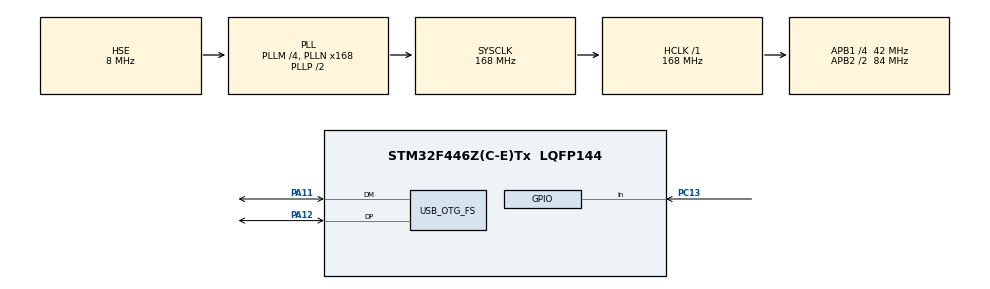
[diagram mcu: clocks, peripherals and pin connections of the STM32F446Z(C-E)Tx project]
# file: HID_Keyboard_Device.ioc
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Mcu.Family=STM32F4
Mcu.Name=STM32F446Z(C-E)Tx
Mcu.Package=LQFP144
NVIC.OTG_FS_IRQn=true\:0\:0\:false\:false\:true\:false\:true
NVIC.PriorityGroup=NVIC_PRIORITYGROUP_4
PA11.Mode=Device_Only
PA11.Signal=USB_OTG_FS_DM
PA12.Mode=Device_Only
PA12.Signal=USB_OTG_FS_DP
PC13.Signal=GPIO_Input
PH0-OSC_IN.Mode=HSE-External-Clock-Source
PH0-OSC_IN.Signal=RCC_OSC_IN
PH1-OSC_OUT.Mode=HSE-External-Clock-Source
PH1-OSC_OUT.Signal=RCC_OSC_OUT
ProjectManager.HeapSize=0x200
ProjectManager.StackSize=0x400
ProjectManager.TargetToolchain=STM32CubeIDE
RCC.AHBFreq_Value=168000000
RCC.APB1CLKDivider=RCC_HCLK_DIV4
RCC.APB1Freq_Value=42000000
RCC.APB1TimFreq_Value=84000000
RCC.APB2CLKDivider=RCC_HCLK_DIV2
RCC.APB2Freq_Value=84000000
RCC.APB2TimFreq_Value=168000000
RCC.CortexFreq_Value=168000000
RCC.HCLKFreq_Value=168000000
RCC.HSE_VALUE=8000000
RCC.PLLM=4
RCC.PLLN=168
RCC.PLLQ=7
RCC.SYSCLKFreq_VALUE=168000000
RCC.SYSCLKSource=RCC_SYSCLKSOURCE_PLLCLK
RCC.USBFreq_Value=48000000
RCC.VCOOutputFreq_Value=336000000
USB_DEVICE.CLASS_NAME_FS=HID
USB_DEVICE.PID_HID_FS=22316
USB_DEVICE.VirtualMode-HID_FS=Hid
USB_DEVICE.VirtualModeFS=Hid_FS
USB_OTG_FS.VirtualMode=Device_Only
VP_USB_DEVICE_VS_USB_DEVICE_HID_FS.Mode=HID_FS
board=HID_Keyboard_Device

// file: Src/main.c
/* USER CODE BEGIN Header */
/**
  ******************************************************************************
  * @file           : main.c
  * @brief          : Main program body
  ******************************************************************************
  * @attention
  *
  * <h2><center>&copy; Copyright (c) 2019 STMicroelectronics.
  * All rights reserved.</center></h2>
  *
  * This software component is licensed by ST under Ultimate Liberty license
  * SLA0044, the "License"; You may not use this file except in compliance with
  * the License. You may obtain a copy of the License at:
  *                             www.st.com/SLA0044
  *
  ******************************************************************************
  */
/* USER CODE END Header */

#include "main.h"
#include "usb_device.h"

/* USER CODE BEGIN Includes */
#include "usbd_hid.h"
/* USER CODE END Includes */

/* USER CODE BEGIN PV */
/* Private variables ---------------------------------------------------------*/
extern USBD_HandleTypeDef hUsbDeviceFS;
/* USER CODE END PV */

void SystemClock_Config(void);
static void MX_GPIO_Init(void);
/* USER CODE BEGIN PFP */
/* Private function prototypes -----------------------------------------------*/
uint8_t buffer[8];
/* USER CODE END PFP */

int main(void)
{

  /* MCU Configuration--------------------------------------------------------*/

  /* Reset of all peripherals, Initializes the Flash interface and the Systick. */
  HAL_Init();

  /* Configure the system clock */
  SystemClock_Config();

  /* Initialize all configured peripherals */
  MX_GPIO_Init();
  MX_USB_DEVICE_Init();
  /* USER CODE BEGIN 2 */
  buffer[0]=1;//reportID
  buffer[1]=0;//modifier
  buffer[2]=0;//OEM
  buffer[3]=0;//keycode data
  buffer[4]=0;//keycode data
  buffer[5]=0;//keycode data
  buffer[6]=0;//keycode data
  buffer[7]=0;//keycode data

  /* USER CODE END 2 */

  /* Infinite loop */
  while (1)
  {

    /* USER CODE BEGIN 3 */
  if(HAL_GPIO_ReadPin(GPIOC,GPIO_PIN_13)==GPIO_PIN_SET)    {
	// Begin TODO 5 HID_KEYBOARD_HANDS_ON: Report PgDown press and release
     #warning "TODO 5 HID_KEYBOARD_HANDS_ON: Report PgDown press and release"
	  //report keycode data - PgDwn press (0x4E)
	  buffer[3]=0x4E;//keycode data
	  USBD_HID_SendReport(&hUsbDeviceFS,buffer,8);
	  HAL_Delay(100);
	  buffer[3]=0x0;//keycode data
	  USBD_HID_SendReport(&hUsbDeviceFS,buffer,8);
	  HAL_Delay(100);
	  //report keycode data -  PgDwn release
	//End HID_KEYBOARD_HANDS_ON: Report PgDown press and release
  }

  }
  /* USER CODE END 3 */
}

void SystemClock_Config(void)
{
  RCC_OscInitTypeDef RCC_OscInitStruct = {0};
  RCC_ClkInitTypeDef RCC_ClkInitStruct = {0};
  RCC_PeriphCLKInitTypeDef PeriphClkInitStruct = {0};

  /** Configure the main internal regulator output voltage
  */
  __HAL_RCC_PWR_CLK_ENABLE();
  __HAL_PWR_VOLTAGESCALING_CONFIG(PWR_REGULATOR_VOLTAGE_SCALE1);
  /** Initializes the CPU, AHB and APB busses clocks
  */
  RCC_OscInitStruct.OscillatorType = RCC_OSCILLATORTYPE_HSE;
  RCC_OscInitStruct.HSEState = RCC_HSE_BYPASS;
  RCC_OscInitStruct.PLL.PLLState = RCC_PLL_ON;
  RCC_OscInitStruct.PLL.PLLSource = RCC_PLLSOURCE_HSE;
  RCC_OscInitStruct.PLL.PLLM = 4;
  RCC_OscInitStruct.PLL.PLLN = 168;
  RCC_OscInitStruct.PLL.PLLP = RCC_PLLP_DIV2;
  RCC_OscInitStruct.PLL.PLLQ = 7;
  RCC_OscInitStruct.PLL.PLLR = 2;
  if (HAL_RCC_OscConfig(&RCC_OscInitStruct) != HAL_OK)
  {
    Error_Handler();
  }
  /** Initializes the CPU, AHB and APB busses clocks
  */
  RCC_ClkInitStruct.ClockType = RCC_CLOCKTYPE_HCLK|RCC_CLOCKTYPE_SYSCLK
                              |RCC_CLOCKTYPE_PCLK1|RCC_CLOCKTYPE_PCLK2;
  RCC_ClkInitStruct.SYSCLKSource = RCC_SYSCLKSOURCE_PLLCLK;
  RCC_ClkInitStruct.AHBCLKDivider = RCC_SYSCLK_DIV1;
  RCC_ClkInitStruct.APB1CLKDivider = RCC_HCLK_DIV4;
  RCC_ClkInitStruct.APB2CLKDivider = RCC_HCLK_DIV2;

  if (HAL_RCC_ClockConfig(&RCC_ClkInitStruct, FLASH_LATENCY_5) != HAL_OK)
  {
    Error_Handler();
  }
  PeriphClkInitStruct.PeriphClockSelection = RCC_PERIPHCLK_CLK48;
  PeriphClkInitStruct.Clk48ClockSelection = RCC_CLK48CLKSOURCE_PLLQ;
  if (HAL_RCCEx_PeriphCLKConfig(&PeriphClkInitStruct) != HAL_OK)
  {
    Error_Handler();
  }
}

static void MX_GPIO_Init(void)
{
  GPIO_InitTypeDef GPIO_InitStruct = {0};

  /* GPIO Ports Clock Enable */
  __HAL_RCC_GPIOC_CLK_ENABLE();
  __HAL_RCC_GPIOH_CLK_ENABLE();
  __HAL_RCC_GPIOA_CLK_ENABLE();

  /*Configure GPIO pin : PC13 */
  GPIO_InitStruct.Pin = GPIO_PIN_13;
  GPIO_InitStruct.Mode = GPIO_MODE_INPUT;
  GPIO_InitStruct.Pull = GPIO_NOPULL;
  HAL_GPIO_Init(GPIOC, &GPIO_InitStruct);

}

void Error_Handler(void)
{
  while(1)
  {
  }
}

/************************ (C) COPYRIGHT STMicroelectronics *****END OF FILE****/
